AUTOSAR XML (schema 4-2-2)
package /ServiceApplTemplate/SwComponentTypes
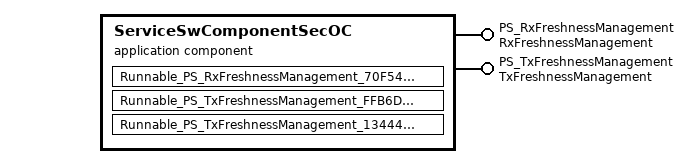
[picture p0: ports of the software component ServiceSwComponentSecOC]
  application sw component type ServiceSwComponentSecOC
    provide port PS_RxFreshnessManagement: provided-interface=RxFreshnessManagement
    provide port PS_TxFreshnessManagement: provided-interface=TxFreshnessManagement
    behavior ServiceSwComponentSecOC_IB: handle-termination-and-restart=NO-SUPPORT
      operation invoked event OIE_PS_RxFreshnessManagement_70F547DC410F0DD5A5B53E9A8C6EF542: start-on-event=Runnable_PS_RxFreshnessManagement_70F547DC410F0DD5A5B53E9A8C6EF542, operation=PS_RxFreshnessManagement.GetRxFreshness
      operation invoked event OIE_PS_TxFreshnessManagement_FFB6DDB35A62C3E71630345752F29B21: start-on-event=Runnable_PS_TxFreshnessManagement_FFB6DDB35A62C3E71630345752F29B21, operation=PS_TxFreshnessManagement.GetTxFreshness
      operation invoked event OIE_PS_TxFreshnessManagement_13444CA5556084B6AA2EAB622794141A: start-on-event=Runnable_PS_TxFreshnessManagement_13444CA5556084B6AA2EAB622794141A, operation=PS_TxFreshnessManagement.SPduTxConfirmation
      runnable Runnable_PS_RxFreshnessManagement_70F547DC410F0DD5A5B53E9A8C6EF542: symbol=ServiceSwComponentSecOC_PS_RxFreshnessManagement_GetRxFreshness
      runnable Runnable_PS_TxFreshnessManagement_FFB6DDB35A62C3E71630345752F29B21: symbol=ServiceSwComponentSecOC_PS_TxFreshnessManagement_GetTxFreshness
      runnable Runnable_PS_TxFreshnessManagement_13444CA5556084B6AA2EAB622794141A: symbol=ServiceSwComponentSecOC_PS_TxFreshnessManagement_SPduTxConfirmation
  swc implementation ServiceSwComponentSecOC_Impl: programming-language=C, sw-version=1.0.0, vendor-id=1, behavior=ServiceSwComponentSecOC_IB
    code-descriptors:
      code CodeDescriptor: artifact-descriptors=autosar-engineering-object={short-label=EngObject, category=SWSRC}
    resource consumption ResourceConsumption
      memory section Code: sw-addrmethod=CODE, symbol=CODE
package /DemoApplication/SwComponentTypes
  composition sw component type TopLevelComposition
    component ServiceSwComponentSecOC: type=ServiceSwComponentSecOC
    connect ServiceSwComponentSecOC.PS_RxFreshnessManagement -> SecOC_Prototype.PS_RxFreshnessManagement
    connect ServiceSwComponentSecOC.PS_TxFreshnessManagement -> SecOC_Prototype.PS_TxFreshnessManagement
package /CanSystem
  system CanSystem
    system mapping ServiceSwComponentSecOCSystemMappings
      sw-mappings:
        swc to ecu mapping ServiceSwComponentSecOCSwcToEcuMapping: component=TopLevelComposition.ServiceSwComponentSecOC, ecu-instance=EcuTestNode
